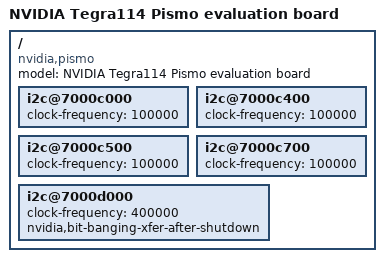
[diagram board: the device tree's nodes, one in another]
/dts-v1/;

/include/ "tegra114.dtsi"

/ {
	model = "NVIDIA Tegra114 Pismo evaluation board";
	compatible = "nvidia,pismo", "nvidia,tegra114";

	i2c@7000c000 {
		status = "okay";
		clock-frequency = <100000>;
	};

	i2c@7000c400 {
		status = "okay";
		clock-frequency = <100000>;
	};

	i2c@7000c500 {
		status = "okay";
		clock-frequency = <100000>;
	};

	i2c@7000c700 {
		status = "okay";
		clock-frequency = <100000>;
	};

	i2c@7000d000 {
		status = "okay";
		clock-frequency = <400000>;
		nvidia,bit-banging-xfer-after-shutdown;
	};
};
